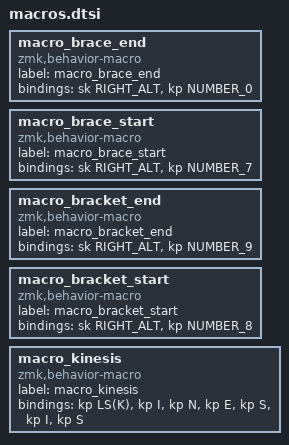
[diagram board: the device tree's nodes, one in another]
macro_brace_end: macro_brace_end{
compatible = "zmk,behavior-macro";
label = "macro_brace_end";
#binding-cells = <0>;
bindings = <&sk RIGHT_ALT>, <&kp NUMBER_0>;
};
macro_brace_start: macro_brace_start{
compatible = "zmk,behavior-macro";
label = "macro_brace_start";
#binding-cells = <0>;
bindings = <&sk RIGHT_ALT>, <&kp NUMBER_7>;
};
macro_bracket_end: macro_bracket_end{
compatible = "zmk,behavior-macro";
label = "macro_bracket_end";
#binding-cells = <0>;
bindings = <&sk RIGHT_ALT>, <&kp NUMBER_9>;
};
macro_bracket_start: macro_bracket_start{
compatible = "zmk,behavior-macro";
label = "macro_bracket_start";
#binding-cells = <0>;
bindings = <&sk RIGHT_ALT>, <&kp NUMBER_8>;
};
macro_kinesis: macro_kinesis{
compatible = "zmk,behavior-macro";
label = "macro_kinesis";
#binding-cells = <0>;
bindings = <&kp LS(K)>, <&kp I>, <&kp N>, <&kp E>, <&kp S>, <&kp I>, <&kp S>;
};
